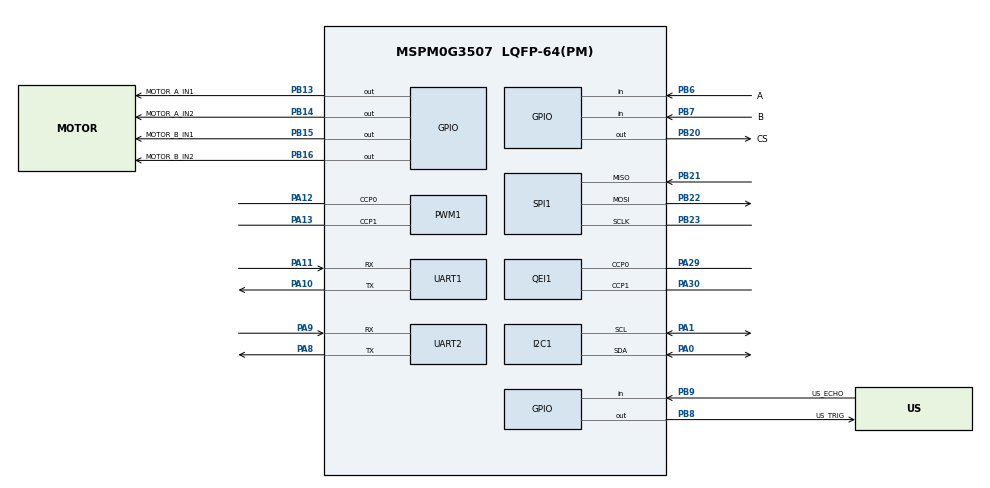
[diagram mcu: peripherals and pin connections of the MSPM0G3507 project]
/**
 * 天猛星 MSPM0G3507 工作台基线配置（CCS / SysConfig 1.2x，MSPM0 SDK 2.11）。
 * 【未验证】手写，按 TI 例程格式；未在 SysConfig GUI 打开过、未上板。引脚与 ../board.yaml 一致，
 * 由 `make check` 中 `syscfg_import.py --check ../board.yaml` 比对。打开后若 SysConfig 报冲突，以 GUI 为准改好再回写 board.yaml。
 */
//@cliArgs --device "MSPM0G350X" --package "LQFP-64(PM)" --part "Default"
//@v2CliArgs --device "MSPM0G3507" --package "LQFP-64(PM)"
// @cliArgs --rtos nortos

const GPIO   = scripting.addModule("/ti/driverlib/GPIO", {}, false);
const GPIO1  = GPIO.addInstance();
const GPIO2  = GPIO.addInstance();
const GPIO3  = GPIO.addInstance();
const GPIO4  = GPIO.addInstance();
const GPIO5  = GPIO.addInstance();
const GPIO6  = GPIO.addInstance();
const GPIO7  = GPIO.addInstance();
const GPIO8  = GPIO.addInstance();
const ADC12  = scripting.addModule("/ti/driverlib/ADC12", {}, false);
const DAC12  = scripting.addModule("/ti/driverlib/DAC12");
const ADC121 = ADC12.addInstance();
const I2C    = scripting.addModule("/ti/driverlib/I2C", {}, false);
const I2C1   = I2C.addInstance();
const SPI    = scripting.addModule("/ti/driverlib/SPI", {}, false);
const SPI1   = SPI.addInstance();
const PWM    = scripting.addModule("/ti/driverlib/PWM", {}, false);
const PWM1   = PWM.addInstance();
const QEI    = scripting.addModule("/ti/driverlib/QEI", {}, false);
const QEI1   = QEI.addInstance();
const SYSCTL = scripting.addModule("/ti/driverlib/SYSCTL");
const TIMER  = scripting.addModule("/ti/driverlib/TIMER", {}, false);
const TIMER1 = TIMER.addInstance();
const UART   = scripting.addModule("/ti/driverlib/UART", {}, false);
const UART1  = UART.addInstance();
const UART2  = UART.addInstance();

GPIO1.$name                         = "GPIO_MOTOR_A_IN1";
GPIO1.associatedPins[0].$name       = "MOTOR_A_IN1";
GPIO1.associatedPins[0].pin.$assign = "PB13";
GPIO2.$name                         = "GPIO_MOTOR_A_IN2";
GPIO2.associatedPins[0].$name       = "MOTOR_A_IN2";
GPIO2.associatedPins[0].pin.$assign = "PB14";
GPIO3.$name                         = "GPIO_MOTOR_B_IN1";
GPIO3.associatedPins[0].$name       = "MOTOR_B_IN1";
GPIO3.associatedPins[0].pin.$assign = "PB15";
GPIO4.$name                         = "GPIO_MOTOR_B_IN2";
GPIO4.associatedPins[0].$name       = "MOTOR_B_IN2";
GPIO4.associatedPins[0].pin.$assign = "PB16";

GPIO5.$name                              = "ENC_MOTOR_B";
GPIO5.associatedPins.create(2);
GPIO5.associatedPins[0].$name            = "A";
GPIO5.associatedPins[0].direction        = "INPUT";
GPIO5.associatedPins[0].interruptEn      = true;
GPIO5.associatedPins[0].polarity         = "RISE_FALL";
GPIO5.associatedPins[0].pin.$assign      = "PB6";
GPIO5.associatedPins[1].$name            = "B";
GPIO5.associatedPins[1].direction        = "INPUT";
GPIO5.associatedPins[1].interruptEn      = true;
GPIO5.associatedPins[1].polarity         = "RISE_FALL";
GPIO5.associatedPins[1].pin.$assign      = "PB7";

PWM1.$name                      = "PWM_TIMG0";
PWM1.timerCount                 = 1600;      /* 32 MHz / 1600 = 20 kHz（假定 BUSCLK 32 MHz、不分频）*/
PWM1.peripheral.$assign         = "TIMG0";
PWM1.peripheral.ccp0Pin.$assign = "PA12";
PWM1.peripheral.ccp1Pin.$assign = "PA13";

QEI1.$name                      = "ENC_MOTOR_A";
QEI1.peripheral.$assign         = "TIMG8";
QEI1.peripheral.ccp0Pin.$assign = "PA29";
QEI1.peripheral.ccp1Pin.$assign = "PA30";

SYSCTL.forceDefaultClkConfig = true;

TIMER1.$name              = "TIMER_CTRL";
TIMER1.profile            = "Basic_Periodic";
TIMER1.timerClkPrescale   = 32;              /* 1 MHz */
TIMER1.timerPeriod        = "1 ms";
TIMER1.interrupts         = ["ZERO"];
TIMER1.peripheral.$assign = "TIMG7";

UART1.$name                    = "UART_LINK";
UART1.targetBaudRate           = 115200;
UART1.enabledInterrupts        = ["RX"];
UART1.peripheral.$assign       = "UART0";
UART1.peripheral.rxPin.$assign = "PA11";
UART1.peripheral.txPin.$assign = "PA10";

/* I2C0 主机 400 kHz：板外 MPU6050 等（PA0/PA1 是开漏脚，需外部上拉；【未验证】未上板） */
I2C1.$name                           = "I2C_IMU";
I2C1.basicEnableController           = true;
I2C1.basicControllerStandardBusSpeed = "Fast";
I2C1.peripheral.$assign              = "I2C0";
I2C1.peripheral.sdaPin.$assign       = "PA0";
I2C1.peripheral.sclPin.$assign       = "PA1";

/* SPI1 主机 mode 3、1 MHz，3 线 + 软件片选（GPIO_CS_<SPI实例>_<设备名>，引脚名 CS）；【未验证】未上板 */
SPI1.$name                      = "SPI_BUS1";
SPI1.frameFormat                = "MOTO3";
SPI1.polarity                   = "1";
SPI1.phase                      = "1";
SPI1.targetBitRate              = 1000000;
SPI1.peripheral.$assign         = "SPI1";
SPI1.peripheral.sclkPin.$assign = "PB23";
SPI1.peripheral.mosiPin.$assign = "PB22";
SPI1.peripheral.misoPin.$assign = "PB21";

GPIO6.$name                         = "GPIO_CS_SPI1_DEV";
GPIO6.associatedPins[0].$name       = "CS";
GPIO6.associatedPins[0].initialValue = "SET";
GPIO6.associatedPins[0].pin.$assign = "PB20";

/* UART1：IMU 姿态模块口（本板当主控时接收 dzimu；跑 apps/imu_module 时发送）；【未验证】未上板 */
UART2.$name                    = "UART_IMU";
UART2.targetBaudRate           = 460800;
UART2.enabledInterrupts        = ["RX"];
UART2.peripheral.$assign       = "UART1";
UART2.peripheral.rxPin.$assign = "PA9";
UART2.peripheral.txPin.$assign = "PA8";

/* 超声波 HC-SR04（v0.6.0）：TRIG 输出、ECHO 输入（双边沿中断由 pal_gpio_irq_attach 运行时打开）；【未验证】引脚未对照原理图 */
GPIO7.$name                         = "GPIO_US_TRIG";
GPIO7.associatedPins[0].$name       = "US_TRIG";
GPIO7.associatedPins[0].pin.$assign = "PB8";
GPIO8.$name                         = "GPIO_US_ECHO";
GPIO8.associatedPins[0].$name       = "US_ECHO";
GPIO8.associatedPins[0].direction   = "INPUT";
GPIO8.associatedPins[0].pin.$assign = "PB9";

/* ADC0：电池电压（单次软件触发；pal_adc_read 运行时改 MEM0 通道）；【未验证】引脚未对照原理图 */
ADC121.$name                 = "ADC12_0";
ADC121.adcMem0chansel        = "DL_ADC12_INPUT_CHAN_2";
ADC121.peripheral.$assign    = "ADC0";
ADC121.peripheral.adcPin2.$assign = "PA25";

/* DAC12：12 位、VDDA 参考、输出缓冲开，OUT0 = PA15（pal_dac_write 直写 DATA0）；【未测】未在 SysConfig 里打开过，属性名没核对，导入后以 SysConfig 界面为准 */
DAC12.dacOutputPinEn         = true;
DAC12.dacAmplifier           = "ON";
DAC12.dacOutput12            = 0;

/* 掉电保存区（board.yaml mcu.nvm_kb）：链接文件用 tools/gen_ide_nvm.py 生成的 dz_nvm_linker.cmd（FLASH 末尾让出），
 * 不让 SysConfig 再生成一份（两份 MEMORY 会冲突）。【未测】未在 CCS 里打开过。 */
const ProjectConfig = scripting.addModule("/ti/project_config/ProjectConfig");
ProjectConfig.genLinker = false;
